# ATmega1284RFR2 device description
Architecture: AVR8; Family: megaAVR
Registers are 8-bit, access not given, no defined reset value unless marked. A register's access mark holds for its fields unless they carry their own. Offsets are from the block's base; [hi:lo] are bit positions; 'fields as' and 'values as' point back to an identical list.

## TC4 (TC16 module) — Timer/Counter, 16-bit
Instances: TC4 0x00
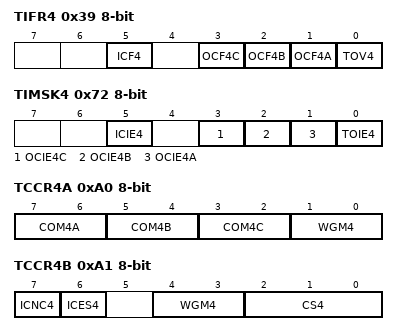
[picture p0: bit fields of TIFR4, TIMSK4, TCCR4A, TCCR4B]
0x39 TIFR4 — Timer/Counter4 Interrupt Flag Register
  [5] ICF4 — Timer/Counter4 Input Capture Flag
  [3] OCF4C — Timer/Counter4 Output Compare C Match Flag
  [2] OCF4B — Timer/Counter4 Output Compare B Match Flag
  [1] OCF4A — Timer/Counter4 Output Compare A Match Flag
  [0] TOV4 — Timer/Counter4 Overflow Flag
0x72 TIMSK4 — Timer/Counter4 Interrupt Mask Register
  [5] ICIE4 — Timer/Counter4 Input Capture Interrupt Enable
  [3] OCIE4C — Timer/Counter4 Output Compare C Match Interrupt Enable
  [2] OCIE4B — Timer/Counter4 Output Compare B Match Interrupt Enable
  [1] OCIE4A — Timer/Counter4 Output Compare A Match Interrupt Enable
  [0] TOIE4 — Timer/Counter4 Overflow Interrupt Enable
0xA0 TCCR4A — Timer/Counter4 Control Register A
  [7:6] COM4A — Compare Output Mode for Channel A
    0=Normal operation
  [5:4] COM4B — Compare Output Mode for Channel B
    0=Normal operation
  [3:2] COM4C — Compare Output Mode for Channel C
    0=Normal operation
  [1:0] WGM4 — Waveform Generation Mode
    0=Normal mode of operation; 1=PWM, phase correct, 8-bit; 2=PWM, phase correct, 9-bit; 3=PWM, phase correct, 10-bit; 4=CTC, TOP = OCRnA; 5=Fast PWM, 8-bit; 6=Fast PWM, 9-bit; 7=Fast PWM, 10-bit; 8=PWM, Phase and frequency correct, TOP = ICRn; 9=PWM, Phase and frequency correct, TOP = OCRnA; 10=PWM, Phase correct, TOP = ICRn; 11=PWM, Phase correct, TOP = OCRnA; 12=CTC, TOP = OCRnA; 14=Fast PWM, TOP = ICRn; 15=Fast PWM, TOP = OCRnA
0xA1 TCCR4B — Timer/Counter4 Control Register B
  [7] ICNC4 — Input Capture 4 Noise Canceller
  [6] ICES4 — Input Capture 4 Edge Select
  [4:3] WGM4 (bit 2 of the value upward) — Waveform Generation Mode
    values as TCCR4A.WGM4
  [2:0] CS4 — Clock Select
    0=No clock source (Timer/Counter stopped); 1=clk_IO/1 (no prescaling); 2=clk_IO/8 (from prescaler); 3=clk_IO/64 (from prescaler); 4=clk_IO/256 (from prescaler); 5=clk_IO/1024 (from prescaler)
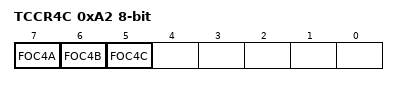
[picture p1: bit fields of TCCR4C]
0xA2 TCCR4C — Timer/Counter4 Control Register C
  [7] FOC4A — Force Output Compare for Channel A
  [6] FOC4B — Force Output Compare for Channel B
  [5] FOC4C — Force Output Compare for Channel C
0xA4 TCNT4 16-bit — Timer/Counter4 Bytes
0xA6 ICR4 16-bit — Timer/Counter4 Input Capture Register Bytes
0xA8 OCR4A 16-bit — Timer/Counter4 Output Compare Register A Bytes
0xAA OCR4B 16-bit — Timer/Counter4 Output Compare Register B Bytes
0xAC OCR4C 16-bit — Timer/Counter4 Output Compare Register C Bytes

## TC3 (TC16 module) — Timer/Counter, 16-bit
Instances: TC3 0x00
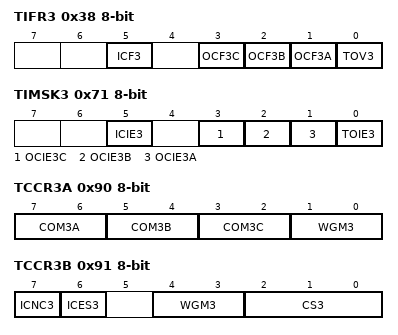
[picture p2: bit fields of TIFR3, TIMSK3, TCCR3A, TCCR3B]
0x38 TIFR3 — Timer/Counter3 Interrupt Flag Register
  [5] ICF3 — Timer/Counter3 Input Capture Flag
  [3] OCF3C — Timer/Counter3 Output Compare C Match Flag
  [2] OCF3B — Timer/Counter3 Output Compare B Match Flag
  [1] OCF3A — Timer/Counter3 Output Compare A Match Flag
  [0] TOV3 — Timer/Counter3 Overflow Flag
0x71 TIMSK3 — Timer/Counter3 Interrupt Mask Register
  [5] ICIE3 — Timer/Counter3 Input Capture Interrupt Enable
  [3] OCIE3C — Timer/Counter3 Output Compare C Match Interrupt Enable
  [2] OCIE3B — Timer/Counter3 Output Compare B Match Interrupt Enable
  [1] OCIE3A — Timer/Counter3 Output Compare A Match Interrupt Enable
  [0] TOIE3 — Timer/Counter3 Overflow Interrupt Enable
0x90 TCCR3A — Timer/Counter3 Control Register A
  [7:6] COM3A — Compare Output Mode for Channel A
    0=Normal port operation, OCnA/OCnB/OCnC disconnected; 1=Toggle OCnA/OCnB/OCnC on Compare Match; 2=Clear OCnA/OCnB/OCnC on Compare Match (set output to low level); 3=Set OCnA/OCnB/OCnC on Compare Match (set output to high level)
  [5:4] COM3B — Compare Output Mode for Channel B
    values as COM3A
  [3:2] COM3C — Compare Output Mode for Channel C
    values as COM3A
  [1:0] WGM3 — Waveform Generation Mode
    0=Normal mode of operation; 1=PWM, phase correct, 8-bit; 2=PWM, phase correct, 9-bit; 3=PWM, phase correct, 10-bit; 4=CTC, TOP = OCRnA; 5=Fast PWM, 8-bit; 6=Fast PWM, 9-bit; 7=Fast PWM, 10-bit; 8=PWM, Phase and frequency correct, TOP = ICRn; 9=PWM, Phase and frequency correct, TOP = OCRnA; 10=PWM, Phase correct, TOP = ICRn; 11=PWM, Phase correct, TOP = OCRnA; 12=CTC, TOP = OCRnA; 14=Fast PWM, TOP = ICRn; 15=Fast PWM, TOP = OCRnA
0x91 TCCR3B — Timer/Counter3 Control Register B
  [7] ICNC3 — Input Capture 3 Noise Canceller
  [6] ICES3 — Input Capture 3 Edge Select
  [4:3] WGM3 (bit 2 of the value upward) — Waveform Generation Mode
    values as TCCR3A.WGM3
  [2:0] CS3 — Clock Select
    0=No clock source (Timer/Counter stopped); 1=clk_IO/1 (no prescaling); 2=clk_IO/8 (from prescaler); 3=clk_IO/64 (from prescaler); 4=clk_IO/256 (from prescaler); 5=clk_IO/1024 (from prescaler); 6=External clock source on Tn pin, clock on falling edge; 7=External clock source on Tn pin, clock on rising edge
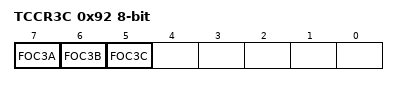
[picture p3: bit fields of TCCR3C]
0x92 TCCR3C — Timer/Counter3 Control Register C
  [7] FOC3A — Force Output Compare for Channel A
  [6] FOC3B — Force Output Compare for Channel B
  [5] FOC3C — Force Output Compare for Channel C
0x94 TCNT3 16-bit — Timer/Counter3 Bytes
0x96 ICR3 16-bit — Timer/Counter3 Input Capture Register Bytes
0x98 OCR3A 16-bit — Timer/Counter3 Output Compare Register A Bytes
0x9A OCR3B 16-bit — Timer/Counter3 Output Compare Register B Bytes
0x9C OCR3C 16-bit — Timer/Counter3 Output Compare Register C Bytes
